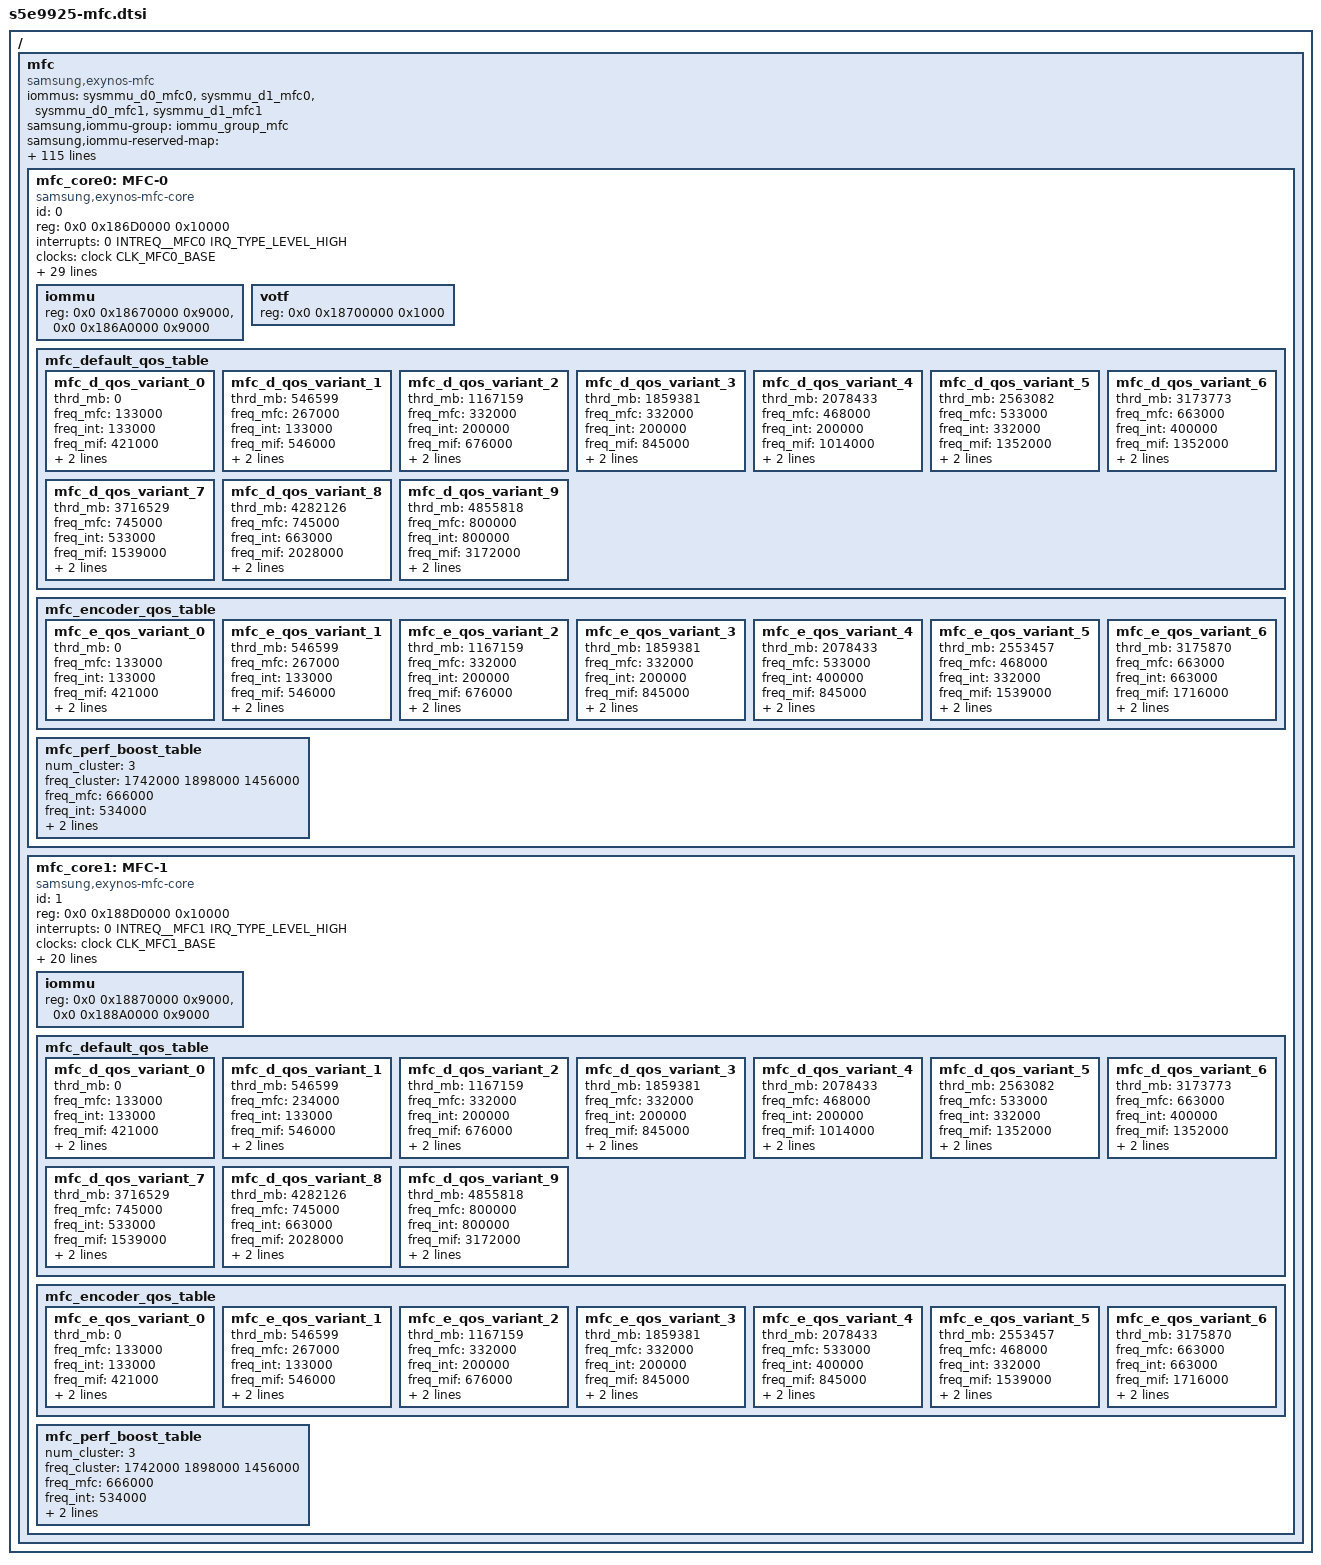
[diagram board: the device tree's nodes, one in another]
/*
 * SAMSUNG EXYNOS SoC mfc device tree source
 *
 * Copyright (c) 2018 Samsung Electronics Co., Ltd.
 *		http://www.samsung.com
 *
 * SAMSUNG EXYNOS SoC mfc device nodes are listed in this file.
 * EXYNOS based board files can include this file and provide
 * values for board specfic bindings.
 *
 * This program is free software; you can redistribute it and/or modify
 * it under the terms of the GNU General Public License version 2 as
 * published by the Free Software Foundation.
 */

#include <dt-bindings/clock/s5e9925.h>
#include <dt-bindings/interrupt-controller/s5e9925.h>

/ {
	mfc: mfc {
		/* Basic setting */
		compatible = "samsung,exynos-mfc";

		/* for vb2 device */
		iommus = <&sysmmu_d0_mfc0>, <&sysmmu_d1_mfc0>,
		       <&sysmmu_d0_mfc1>, <&sysmmu_d1_mfc1>;
		samsung,iommu-group = <&iommu_group_mfc>;
		samsung,iommu-reserved-map = <0x0 0x0 0x10000000>,
				<0x0 0x10000000 0x100000>,
				<0x0 0x10100000 0x100000>;
		samsung,iommu-identity-map = <0x0 0x1771F000 0x10000>,
					<0x0 0x1AD2F000 0x10000>;

		samsung,tzmp;

		/* for F/W buffer */
		memory-region = <&mfc_fw_rmem>;

		/* MFC version */
		ip_ver = <0x1600010C>;

		/* Debug mode (disable needs sysmmu,async-fault) */
		debug_mode = <0>;

		/* NAL-Q size */
		nal_q_entry_size = <768>;
		nal_q_dump_size = <376>;

		/* Features <on/off version> */
		nal_q = <1 0x0>;
		skype = <1 0x0>;
		black_bar = <1 0x0>;
		color_aspect_dec = <1 0x0>;
		static_info_dec = <1 0x0>;
		color_aspect_enc = <1 0x0>;
		static_info_enc = <1 0x180314>;
		hdr10_plus = <1 0x180709>;
		vp9_stride_align = <1 0x0>;
		sbwc_uncomp = <1 0x190702>;
		mem_clear = <1 0x0>;
		/* Support from v11.0 (except 11.2) */
		wait_fw_status = <1 0x190122>;
		wait_nalq_status = <1 0x191107>;
		/* DRM switch predict for cache flush */
		drm_switch_predict = <1 0x0>;
		/* Support SBWC per-frame control for encoder src */
		sbwc_enc_src_ctrl = <1 0x200110>;
		/* Use metadata interface */
		metadata_interface = <1 0x200910>;
		/* Support HDR10+ full data */
		hdr10_plus_full = <1 0x200910>;
		/* Average QP of encoder per frame */
		average_qp = <1 0x201030>;
		/* MV search mode */
		mv_search_mode = <1 0x201118>;
		/* Support HDR10+ statistic info */
		hdr10_plus_stat_info = <1 0x210402>;
		/* Encoder IDR flag */
		enc_idr_flag = <1 0x210611>;
		/* Encoder min quality mode */
		min_quality_mode = <1 0x210705>;

		/* AV1 Decoder */
		support_av1_dec = <1>;
		/* Support AV1 Film Grain Feature */
		av1_film_grain = <1 0x200717>;

		/* Default 10bit format for decoding (1: P010, 0: 8+2) */
		P010_decoding = <1>;
		/* Dithering option for 8bit display device */
		dithering_enable = <0>;
		/* Decoder stride align (default: 16, AMD GPU: 256) */
		stride_align = <256>;
		/* Decoder stride calculation type (new: 1, old: 0) */
		stride_type = <1>;
		/* Encoder time stamp delta */
		enc_ts_delta = <1 0x211027>;

		/* Formats */
		support_10bit = <1>;
		support_422 = <0>;
		support_rgb = <1>;

		/* SBWC */
		support_sbwc = <1>;
		support_sbwcl = <1>;
		support_sbwcl40 = <1>;

		/* SBWC decoder max resolution */
		sbwc_dec_max_width = <3840>;
		sbwc_dec_max_height = <2160>;
		sbwc_dec_max_inst_num = <1>;
		sbwc_dec_max_framerate = <60>;
		sbwc_dec_hdr10_off = <0>;

		/* HDR10+ num max window */
		max_hdr_win = <1>;

		/* HDR10+ Profile for SEI (0: None, 1: A(58-byte), 2: B(73-byte), 3: 256-byte) */
		hdr10_plus_profile = <3>;

		/* error type for sync_point display */
		/* (1: concealment display, 2: error display, 3: error no display) */
		display_err_type = <2>;

		/* FW base security ctrl */
		security_ctrl = <1>;
		/* output buffer Q framerate */
		display_framerate = <0>;

		/* Encoder default parameter: max number is 100 */
		enc_param_num = <25>;
		enc_param_addr = <0xF7B4 0xF7B8 0xF7B0 0xF798 0xFA2C
				0xF790 0xFA34 0xFA38 0xFA3C 0xF7C0
				0xF7C8 0xF7CC 0xFA60 0xFDD4 0xFDDC
				0xFB54 0xFB58 0xFBA8 0xFD90 0xFD94
				0xFD40 0xFD48 0xFD4C 0xFD50 0xFD80>;
		enc_param_val = <0x80 0x80 0x0 0x4000 0x3FD00
				0x0 0x0 0x2710 0x3E8 0x0
				0x0 0x0 0x0 0x8050D211 0x0
				0x3011 0x0 0x0 0x2D 0xA00
				0x1D 0xF4240 0x33003300 0x2 0x1>;

		/* BW <peak, read, write> : KB/UHD frame */
		bw_enc_h264		= <45456 56112 11170>;
		bw_enc_hevc		= <46756 52766 9763>;
		bw_enc_hevc_10bit	= <53865 64753 12556>;
		bw_enc_vp8		= <64000 67318 22518>;
		bw_enc_vp9		= <72326 59726 16530>;
		bw_enc_vp9_10bit	= <149085 114928 31419>;
		bw_enc_mpeg4		= <44647 55324 9531>;
		bw_dec_h264		= <32605 34381 21263>;
		bw_dec_hevc		= <29973 28851 17538>;
		bw_dec_hevc_10bit	= <52859 46245 31351>;
		bw_dec_vp8		= <28672 30468 22324>;
		bw_dec_vp9		= <18351 18947 16877>;
		bw_dec_vp9_10bit	= <42384 34452 31766>;
		bw_dec_av1		= <23787 19570 15856>;
		bw_dec_av1_10bit	= <41407 35490 29699>;
		bw_dec_mpeg4		= <31540 25368 15770>;

		/* BW <peak, read, write> : KB/UHD frame. For SBWC format */
		/* It is valid when only support_sbwc = <1> */
		sbwc_bw_enc_h264	= <31622 32183 7065>;
		sbwc_bw_enc_hevc	= <24044 27526 5888>;
		sbwc_bw_enc_hevc_10bit	= <32666 37594 8841>;
		sbwc_bw_enc_vp8		= <32666 37594 8841>;
		sbwc_bw_enc_vp9		= <23276 26884 8702>;
		sbwc_bw_enc_vp9_10bit	= <42302 41116 14052>;
		sbwc_bw_enc_mpeg4	= <32666 37594 8841>;
		sbwc_bw_dec_h264	= <23757 18603 13620>;
		sbwc_bw_dec_hevc	= <15309 15387 10279>;
		sbwc_bw_dec_hevc_10bit	= <20808 20602 14868>;
		sbwc_bw_dec_vp8		= <17203 18281 13394>;
		sbwc_bw_dec_vp9		= <11121 9691 8999>;
		sbwc_bw_dec_vp9_10bit	= <17787 15582 14413>;
		sbwc_bw_dec_mpeg4	= <18924 15221 9462>;

		/* QoS bitrate */
		num_mfc_freq = <7>;
		mfc_freqs = <133000 267000 332000 400000 533000 663000 800000>;
		/* spec: H264(240M) VP8(80M) */
		max_Kbps = <245760 81920>;

		/* QoS weight (%) */
		dynamic_weight = <1>;
		qos_weight_h264_hevc = <100>;
		qos_weight_vp8_vp9 = <100>;
		qos_weight_av1 = <70>;
		qos_weight_other_codec = <25>;
		qos_weight_3plane = <80>;
		qos_weight_10bit = <75>;
		qos_weight_422 = <70>;
		qos_weight_bframe = <50>;
		qos_weight_num_of_ref = <60>;
		qos_weight_gpb = <50>;
		qos_weight_num_of_tile = <75>;
		qos_weight_super64_bframe = <60>;
		qos_weight_mbaff = <60>;

		/* core balance(%) for resource managing */
		core_balance = <54>;

		/* MFC IOVA threshold (MB) */
		iova_threshold = <1700>;

		/* need control for mfc idle clock */
		idle_clk_ctrl = <1>;

		/* QoS level for pm_qos dynamic control */
		qos_ctrl_level = <1>;

		/* QoS INT level for verification firmware (KHz) */
		int_freq_fw_verify = <400000>;

		/* Encoder timing info disable */
		enc_timing_dis = <0>;

		/* Sub nodes for MFC core */
		#address-cells = <2>;
		#size-cells = <1>;
		ranges;

		/* MFC core device */
		mfc_core0: MFC-0 {
			/* Basic setting */
			compatible = "samsung,exynos-mfc-core";
			id = <0>;
			reg = <0x0 0x186D0000 0x10000>;
			interrupts = <0 INTREQ__MFC0 IRQ_TYPE_LEVEL_HIGH>;
			clock-names = "aclk_mfc";
			clocks = <&clock CLK_MFC0_BASE>;
			iommus = <&sysmmu_d0_mfc0>, <&sysmmu_d1_mfc0>;
			samsung,iommu-group = <&iommu_group_mfc>;
			samsung,iommu-reserved-map = <0x0 0x10000000 0x100000>;
			samsung,iommu-identity-map = <0x0 0x1771F000 0x10000>,
					<0x0 0x1AD2F000 0x10000>;

			samsung,tzmp;
			samsung,imgloader-s2mpu-support;

			/* MFC version */
			ip_ver = <0x1600010C>;

			/* Sysmmu check */
			share_sysmmu = <0>;
			axid_mask = <0x7>;
			mfc_fault_num = <0x0>;
			trans_info_offset = <0x1004>;
			tsmux_axid = <0x1>;

			/* LLC (Last Level Cache) */
			llc = <1>;
			need_llc_flush = <0>;

			/* vOTF */
			mfc_votf_base = <0x18700000>;
			gdc_votf_base = <0x1771F000>;
			dpu_votf_base = <0x1AD2F000>;

			/* QoS */
			num_default_qos_steps = <10>;
			num_encoder_qos_steps = <7>;
			max_mb = <5093269>;
			max_hw_mb = <3888000>;
			mfc_freq_control = <1>;
			mo_control = <1>;
			bw_control = <1>;

			/* mem-log buffer size */
			memlog_size = <0x80000>;
			memlog_sfr_size = <0x1000>;

			/* Sub nodes for sysmmu, hwfc and mmcache */
			#address-cells = <2>;
			#size-cells = <1>;
			ranges;

			iommu {
			        reg = <0x0 0x18670000 0x9000>,
			            <0x0 0x186A0000 0x9000>;
			};
			votf {
				reg = <0x0 0x18700000 0x1000>;
			};

			/* Default QoS table */
			mfc_default_qos_table {
				mfc_d_qos_variant_0 {
					thrd_mb = <0>;
					freq_mfc = <133000>;
					freq_int = <133000>;
					freq_mif = <421000>;
					bts_scen = "default";
					time_fw = <1238>;
				};
				mfc_d_qos_variant_1 {
					thrd_mb = <546599>;
					freq_mfc = <267000>;
					freq_int = <133000>;
					freq_mif = <546000>;
					bts_scen = "default";
					time_fw = <842>;
				};
				mfc_d_qos_variant_2 {
					thrd_mb = <1167159>;
					freq_mfc = <332000>;
					freq_int = <200000>;
					freq_mif = <676000>;
					bts_scen = "default";
					time_fw = <667>;
				};
				mfc_d_qos_variant_3 {
					thrd_mb = <1859381>;
					freq_mfc = <332000>;
					freq_int = <200000>;
					freq_mif = <845000>;
					bts_scen = "default";
					time_fw = <578>;
				};
				mfc_d_qos_variant_4 {
					thrd_mb = <2078433>;
					freq_mfc = <468000>;
					freq_int = <200000>;
					freq_mif = <1014000>;
					bts_scen = "default";
					time_fw = <483>;
				};
				mfc_d_qos_variant_5 {
					thrd_mb = <2563082>;
					freq_mfc = <533000>;
					freq_int = <332000>;
					freq_mif = <1352000>;
					bts_scen = "default";
					time_fw = <362>;
				};
				mfc_d_qos_variant_6 {
					thrd_mb = <3173773>;
					freq_mfc = <663000>;
					freq_int = <400000>;
					freq_mif = <1352000>;
					bts_scen = "default";
					time_fw = <306>;
				};
				mfc_d_qos_variant_7 {
					thrd_mb = <3716529>;
					freq_mfc = <745000>;
					freq_int = <533000>;
					freq_mif = <1539000>;
					bts_scen = "default";
					time_fw = <267>;
				};
				mfc_d_qos_variant_8 {
					thrd_mb = <4282126>;
					freq_mfc = <745000>;
					freq_int = <663000>;
					freq_mif = <2028000>;
					bts_scen = "default";
					time_fw = <235>;
				};
				mfc_d_qos_variant_9 {
					thrd_mb = <4855818>;
					freq_mfc = <800000>;
					freq_int = <800000>;
					freq_mif = <3172000>;
					bts_scen = "mfc_uhd_10bit";
					time_fw = <175>;
				};
			};

			/* Encoder only QoS table */
			mfc_encoder_qos_table {
				mfc_e_qos_variant_0 {
					thrd_mb = <0>;
					freq_mfc = <133000>;
					freq_int = <133000>;
					freq_mif = <421000>;
					bts_scen = "default";
					time_fw = <1238>;
				};
				mfc_e_qos_variant_1 {
					thrd_mb = <546599>;
					freq_mfc = <267000>;
					freq_int = <133000>;
					freq_mif = <546000>;
					bts_scen = "default";
					time_fw = <842>;
				};
				mfc_e_qos_variant_2 {
					thrd_mb = <1167159>;
					freq_mfc = <332000>;
					freq_int = <200000>;
					freq_mif = <676000>;
					bts_scen = "default";
					time_fw = <667>;
				};
				mfc_e_qos_variant_3 {
					thrd_mb = <1859381>;
					freq_mfc = <332000>;
					freq_int = <200000>;
					freq_mif = <845000>;
					bts_scen = "default";
					time_fw = <578>;
				};
				mfc_e_qos_variant_4 {
					thrd_mb = <2078433>;
					freq_mfc = <533000>;
					freq_int = <400000>;
					freq_mif = <845000>;
					bts_scen = "default";
					time_fw = <471>;
				};
				mfc_e_qos_variant_5 {
					thrd_mb = <2553457>;
					freq_mfc = <468000>;
					freq_int = <332000>;
					freq_mif = <1539000>;
					bts_scen = "mfc_uhd";
					time_fw = <359>;
				};
				mfc_e_qos_variant_6 {
					thrd_mb = <3175870>;
					freq_mfc = <663000>;
					freq_int = <663000>;
					freq_mif = <1716000>;
					bts_scen = "default";
					time_fw = <287>;
				};
			};

			/* QoS table for performance boost mode */
			mfc_perf_boost_table {
				num_cluster = <3>;
				freq_cluster = <1742000 1898000 1456000>;
				freq_mfc = <666000>;
				freq_int = <534000>;
				freq_mif = <2730000>;
				bts_scen = "mfc_uhd_10bit";
			};
		};

		mfc_core1: MFC-1 {
			/* Basic setting */
			compatible = "samsung,exynos-mfc-core";
			id = <1>;
			reg = <0x0 0x188D0000 0x10000>;
			interrupts = <0 INTREQ__MFC1 IRQ_TYPE_LEVEL_HIGH>;
			clock-names = "aclk_mfc";
			clocks = <&clock CLK_MFC1_BASE>;
			iommus = <&sysmmu_d0_mfc1>, <&sysmmu_d1_mfc1>;
			samsung,iommu-group = <&iommu_group_mfc>;
			samsung,iommu-reserved-map = <0x0 0x10100000 0x100000>;

			samsung,tzmp;
			samsung,imgloader-s2mpu-support;

			/* MFC version */
			ip_ver = <0x1600010D>;

			/* Sysmmu check */
			share_sysmmu = <0>;
			axid_mask = <0xFFFF>;
			mfc_fault_num = <0x0>;
			trans_info_offset = <0x1004>;

			/* LLC (Last Level Cache) */
			llc = <1>;
			need_llc_flush = <0>;

			/* QoS */
			num_default_qos_steps = <10>;
			num_encoder_qos_steps = <7>;
			max_mb = <5315425>;
			max_hw_mb = <3888000>;
			mfc_freq_control = <1>;
			mo_control = <1>;
			bw_control = <1>;

			/* Sub nodes for sysmmu, hwfc and mmcache */
			#address-cells = <2>;
			#size-cells = <1>;
			ranges;

			iommu {
			        reg = <0x0 0x18870000 0x9000>,
			            <0x0 0x188A0000 0x9000>;
			};

			/* Default QoS table */
			mfc_default_qos_table {
				mfc_d_qos_variant_0 {
					thrd_mb = <0>;
					freq_mfc = <133000>;
					freq_int = <133000>;
					freq_mif = <421000>;
					bts_scen = "default";
					time_fw = <1238>;
				};
				mfc_d_qos_variant_1 {
					thrd_mb = <546599>;
					freq_mfc = <234000>;
					freq_int = <133000>;
					freq_mif = <546000>;
					bts_scen = "default";
					time_fw = <842>;
				};
				mfc_d_qos_variant_2 {
					thrd_mb = <1167159>;
					freq_mfc = <332000>;
					freq_int = <200000>;
					freq_mif = <676000>;
					bts_scen = "default";
					time_fw = <667>;
				};
				mfc_d_qos_variant_3 {
					thrd_mb = <1859381>;
					freq_mfc = <332000>;
					freq_int = <200000>;
					freq_mif = <845000>;
					bts_scen = "default";
					time_fw = <578>;
				};
				mfc_d_qos_variant_4 {
					thrd_mb = <2078433>;
					freq_mfc = <468000>;
					freq_int = <200000>;
					freq_mif = <1014000>;
					bts_scen = "default";
					time_fw = <483>;
				};
				mfc_d_qos_variant_5 {
					thrd_mb = <2563082>;
					freq_mfc = <533000>;
					freq_int = <332000>;
					freq_mif = <1352000>;
					bts_scen = "default";
					time_fw = <362>;
				};
				mfc_d_qos_variant_6 {
					thrd_mb = <3173773>;
					freq_mfc = <663000>;
					freq_int = <400000>;
					freq_mif = <1352000>;
					bts_scen = "default";
					time_fw = <306>;
				};
				mfc_d_qos_variant_7 {
					thrd_mb = <3716529>;
					freq_mfc = <745000>;
					freq_int = <533000>;
					freq_mif = <1539000>;
					bts_scen = "default";
					time_fw = <267>;
				};
				mfc_d_qos_variant_8 {
					thrd_mb = <4282126>;
					freq_mfc = <745000>;
					freq_int = <663000>;
					freq_mif = <2028000>;
					bts_scen = "default";
					time_fw = <235>;
				};
				mfc_d_qos_variant_9 {
					thrd_mb = <4855818>;
					freq_mfc = <800000>;
					freq_int = <800000>;
					freq_mif = <3172000>;
					bts_scen = "mfc_8k_dec30";
					time_fw = <175>;
				};
			};

			/* Encoder only QoS table */
			mfc_encoder_qos_table {
				mfc_e_qos_variant_0 {
					thrd_mb = <0>;
					freq_mfc = <133000>;
					freq_int = <133000>;
					freq_mif = <421000>;
					bts_scen = "default";
					time_fw = <1238>;
				};
				mfc_e_qos_variant_1 {
					thrd_mb = <546599>;
					freq_mfc = <267000>;
					freq_int = <133000>;
					freq_mif = <546000>;
					bts_scen = "default";
					time_fw = <842>;
				};
				mfc_e_qos_variant_2 {
					thrd_mb = <1167159>;
					freq_mfc = <332000>;
					freq_int = <200000>;
					freq_mif = <676000>;
					bts_scen = "default";
					time_fw = <667>;
				};
				mfc_e_qos_variant_3 {
					thrd_mb = <1859381>;
					freq_mfc = <332000>;
					freq_int = <200000>;
					freq_mif = <845000>;
					bts_scen = "default";
					time_fw = <578>;
				};
				mfc_e_qos_variant_4 {
					thrd_mb = <2078433>;
					freq_mfc = <533000>;
					freq_int = <400000>;
					freq_mif = <845000>;
					bts_scen = "default";
					time_fw = <471>;
				};
				mfc_e_qos_variant_5 {
					thrd_mb = <2553457>;
					freq_mfc = <468000>;
					freq_int = <332000>;
					freq_mif = <1539000>;
					bts_scen = "mfc_uhd";
					time_fw = <359>;
				};
				mfc_e_qos_variant_6 {
					thrd_mb = <3175870>;
					freq_mfc = <663000>;
					freq_int = <663000>;
					freq_mif = <1716000>;
					bts_scen = "default";
					time_fw = <287>;
				};
			};

			/* QoS table for performance boost mode */
			mfc_perf_boost_table {
				num_cluster = <3>;
				freq_cluster = <1742000 1898000 1456000>;
				freq_mfc = <666000>;
				freq_int = <534000>;
				freq_mif = <2730000>;
				bts_scen = "mfc_uhd_10bit";
			};
		};
	};
};
